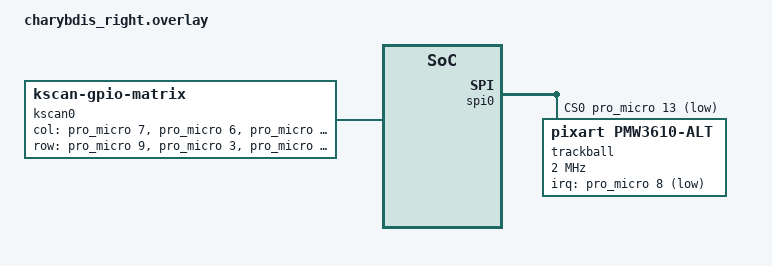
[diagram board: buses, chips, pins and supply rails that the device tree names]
#include "charybdis.dtsi"

&default_transform {
    col-offset = <5>;
};

/ {
    kscan0: kscan {
        compatible = "zmk,kscan-gpio-matrix";
        wakeup-source;
        diode-direction = "row2col";
        col-gpios
            = <&pro_micro 7  (GPIO_ACTIVE_HIGH | GPIO_PULL_DOWN)> 
            , <&pro_micro 6  (GPIO_ACTIVE_HIGH | GPIO_PULL_DOWN)> 
            , <&pro_micro 10 (GPIO_ACTIVE_HIGH | GPIO_PULL_DOWN)> 
            , <&pro_micro 20 (GPIO_ACTIVE_HIGH | GPIO_PULL_DOWN)> 
            , <&pro_micro 19 (GPIO_ACTIVE_HIGH | GPIO_PULL_DOWN)> 
            ;
        row-gpios
            /* MOVED: Row 0 is now Pin 9 (P0.10) to avoid SPI conflict on Pin 2 */
            = <&pro_micro 9  GPIO_ACTIVE_HIGH> 
            , <&pro_micro 3  GPIO_ACTIVE_HIGH> 
            , <&pro_micro 4  GPIO_ACTIVE_HIGH> 
            , <&pro_micro 5  GPIO_ACTIVE_HIGH> 
            ;
    };
};

&trackball_split {
    device = <&trackball>;
};

&spi0 {
    status = "okay";
    compatible = "nordic,nrf-spim";
    pinctrl-0 = <&spi0_default>;
    pinctrl-1 = <&spi0_sleep>;
    pinctrl-names = "default", "sleep";
    
    /* CS: Maps to your old <&gpio0 20> */
    cs-gpios = <&pro_micro 13 GPIO_ACTIVE_LOW>; 

    trackball: trackball@0 {
        status = "okay";
        compatible = "pixart,pmw3610-alt";
        reg = <0>;
        spi-max-frequency = <2000000>;
        
        /* IRQ: Maps to your old <&gpio0 6> (Pin 8) */
        irq-gpios = <&pro_micro 8 (GPIO_ACTIVE_LOW | GPIO_PULL_UP)>;
        
        cpi = <600>;
        evt-type = <INPUT_EV_REL>;
        x-input-code = <INPUT_REL_X>;
        y-input-code = <INPUT_REL_Y>;
    };
};
